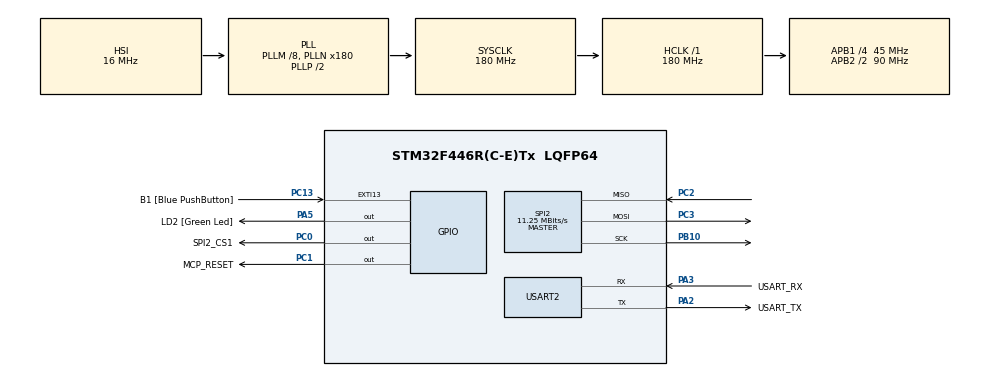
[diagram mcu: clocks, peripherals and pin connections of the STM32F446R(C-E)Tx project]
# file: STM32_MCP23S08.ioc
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Mcu.Family=STM32F4
Mcu.Name=STM32F446R(C-E)Tx
Mcu.Package=LQFP64
NVIC.PriorityGroup=NVIC_PRIORITYGROUP_0
PA13.GPIO_Label=TMS
PA13.Mode=Serial_Wire
PA13.Signal=SYS_JTMS-SWDIO
PA14.GPIO_Label=TCK
PA14.Mode=Serial_Wire
PA14.Signal=SYS_JTCK-SWCLK
PA2.GPIO_Label=USART_TX
PA2.Mode=Asynchronous
PA2.Signal=USART2_TX
PA3.GPIO_Label=USART_RX
PA3.Mode=Asynchronous
PA3.Signal=USART2_RX
PA5.GPIO_Label=LD2 [Green Led]
PA5.Signal=GPIO_Output
PB10.Mode=Full_Duplex_Master
PB10.Signal=SPI2_SCK
PB3.GPIO_Label=SWO
PB3.Signal=SYS_JTDO-SWO
PC0.GPIO_Label=SPI2_CS1
PC0.PinState=GPIO_PIN_SET
PC0.Signal=GPIO_Output
PC1.GPIO_Label=MCP_RESET
PC1.Signal=GPIO_Output
PC13.GPIO_Label=B1 [Blue PushButton]
PC13.GPIO_ModeDefaultEXTI=GPIO_MODE_IT_FALLING
PC13.Signal=GPXTI13
PC14-OSC32_IN.Mode=LSE-External-Oscillator
PC14-OSC32_IN.Signal=RCC_OSC32_IN
PC15-OSC32_OUT.Mode=LSE-External-Oscillator
PC15-OSC32_OUT.Signal=RCC_OSC32_OUT
PC2.Mode=Full_Duplex_Master
PC2.Signal=SPI2_MISO
PC3.Mode=Full_Duplex_Master
PC3.Signal=SPI2_MOSI
PH0-OSC_IN.Mode=HSE-External-Oscillator
PH0-OSC_IN.Signal=RCC_OSC_IN
PH1-OSC_OUT.Mode=HSE-External-Oscillator
PH1-OSC_OUT.Signal=RCC_OSC_OUT
ProjectManager.HeapSize=0x200
ProjectManager.StackSize=0x400
ProjectManager.TargetToolchain=Makefile
RCC.48MHZClocksFreq_Value=84000000
RCC.AHBFreq_Value=180000000
RCC.APB1CLKDivider=RCC_HCLK_DIV4
RCC.APB1Freq_Value=45000000
RCC.APB1TimFreq_Value=90000000
RCC.APB2CLKDivider=RCC_HCLK_DIV2
RCC.APB2Freq_Value=90000000
RCC.APB2TimFreq_Value=180000000
RCC.CortexFreq_Value=180000000
RCC.FLatency-AdvancedSettings=FLASH_LATENCY_5
RCC.HCLKFreq_Value=180000000
RCC.HSE_VALUE=8000000
RCC.HSI_VALUE=16000000
RCC.PLLM=8
RCC.PLLN=180
RCC.SYSCLKFreq_VALUE=180000000
RCC.SYSCLKSource=RCC_SYSCLKSOURCE_PLLCLK
RCC.USBFreq_Value=180000000
RCC.VCOOutputFreq_Value=360000000
SPI2.BaudRatePrescaler=SPI_BAUDRATEPRESCALER_4
SPI2.CalculateBaudRate=11.25 MBits/s
SPI2.Direction=SPI_DIRECTION_2LINES
SPI2.Mode=SPI_MODE_MASTER
SPI2.VirtualType=VM_MASTER
USART2.VirtualMode=VM_ASYNC
board=NUCLEO-F446RE

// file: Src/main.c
/* USER CODE BEGIN Header */
/**
  ******************************************************************************
  * @file           : main.c
  * @brief          : Main program body
  ******************************************************************************
  * @attention
  *
  * Copyright (c) 2023 STMicroelectronics.
  * All rights reserved.
  *
  * This software is licensed under terms that can be found in the LICENSE file
  * in the root directory of this software component.
  * If no LICENSE file comes with this software, it is provided AS-IS.
  *
  ******************************************************************************
  */
/* USER CODE END Header */
#include "main.h"
#include "spi.h"
#include "usart.h"
#include "gpio.h"

/* USER CODE BEGIN Includes */
#include "MCP23S08.h"
#include <stdio.h>
#include "string.h"
/* USER CODE END Includes */

void SystemClock_Config(void);

int main(void)
{

  /* MCU Configuration--------------------------------------------------------*/

  /* Reset of all peripherals, Initializes the Flash interface and the Systick. */
  HAL_Init();

  /* Configure the system clock */
  SystemClock_Config();

  /* Initialize all configured peripherals */
  MX_GPIO_Init();
  MX_SPI2_Init();
  MX_USART2_UART_Init();
  /* USER CODE BEGIN 2 */
  MCP23S08_init(0x40, &hspi2, MCP_RESET_GPIO_Port, MCP_RESET_Pin, 0x03);
  MCP23S08_set_pullup_resistor(0x40, 0x03);
  /* USER CODE END 2 */

  /* Infinite loop */
  /* USER CODE BEGIN WHILE */
  while (1) {
      /*
    uint8_t gpio[8] = {GP0, GP1, GP2, GP3, GP4, GP5, GP6, GP7};

    for (int i=0; i < (sizeof(gpio)/sizeof(gpio[0])); i++) {
        MCP23S08_GPIO_WritePin(0x40, gpio[i], GPIO_PIN_SET);
        HAL_Delay(500);
    }

    for (int i=0; i < 2; i++) {
        for (int j=0; j < (sizeof(gpio)/sizeof(gpio[0])); j++) {
            MCP23S08_GPIO_TogglePin(0x40, gpio[j]);
            HAL_Delay(100);
        }
    }

    for (int i=0; i < (sizeof(gpio)/sizeof(gpio[0])); i++) {
        MCP23S08_GPIO_WritePin(0x40, gpio[i], GPIO_PIN_RESET);
        HAL_Delay(500);
    }
*/
    if (MCP23S08_GPIO_ReadPin(0x40, GP0) == 0) HAL_GPIO_WritePin(LD2_GPIO_Port, LD2_Pin, GPIO_PIN_SET);
    else HAL_GPIO_WritePin(LD2_GPIO_Port, LD2_Pin, GPIO_PIN_RESET);
    if (MCP23S08_GPIO_ReadPin(0x40, GP1) == 0) MCP23S08_GPIO_WritePin(0x40, GP7, GPIO_PIN_SET);
    else MCP23S08_GPIO_WritePin(0x40, GP7, GPIO_PIN_RESET);
    if (MCP23S08_GPIO_ReadPin(0x40, GP0) == -1) {
        while (1) {
            HAL_GPIO_TogglePin(LD2_GPIO_Port, LD2_Pin);
            HAL_Delay(250);
        }
    }
    /* USER CODE END WHILE */

  }
}

void SystemClock_Config(void)
{
  RCC_OscInitTypeDef RCC_OscInitStruct = {0};
  RCC_ClkInitTypeDef RCC_ClkInitStruct = {0};

  /** Configure the main internal regulator output voltage
  */
  __HAL_RCC_PWR_CLK_ENABLE();
  __HAL_PWR_VOLTAGESCALING_CONFIG(PWR_REGULATOR_VOLTAGE_SCALE1);

  /** Initializes the RCC Oscillators according to the specified parameters
  * in the RCC_OscInitTypeDef structure.
  */
  RCC_OscInitStruct.OscillatorType = RCC_OSCILLATORTYPE_HSI;
  RCC_OscInitStruct.HSIState = RCC_HSI_ON;
  RCC_OscInitStruct.HSICalibrationValue = RCC_HSICALIBRATION_DEFAULT;
  RCC_OscInitStruct.PLL.PLLState = RCC_PLL_ON;
  RCC_OscInitStruct.PLL.PLLSource = RCC_PLLSOURCE_HSI;
  RCC_OscInitStruct.PLL.PLLM = 8;
  RCC_OscInitStruct.PLL.PLLN = 180;
  RCC_OscInitStruct.PLL.PLLP = RCC_PLLP_DIV2;
  RCC_OscInitStruct.PLL.PLLQ = 2;
  RCC_OscInitStruct.PLL.PLLR = 2;
  if (HAL_RCC_OscConfig(&RCC_OscInitStruct) != HAL_OK)
  {
    Error_Handler();
  }

  /** Activate the Over-Drive mode
  */
  if (HAL_PWREx_EnableOverDrive() != HAL_OK)
  {
    Error_Handler();
  }

  /** Initializes the CPU, AHB and APB buses clocks
  */
  RCC_ClkInitStruct.ClockType = RCC_CLOCKTYPE_HCLK|RCC_CLOCKTYPE_SYSCLK
                              |RCC_CLOCKTYPE_PCLK1|RCC_CLOCKTYPE_PCLK2;
  RCC_ClkInitStruct.SYSCLKSource = RCC_SYSCLKSOURCE_PLLCLK;
  RCC_ClkInitStruct.AHBCLKDivider = RCC_SYSCLK_DIV1;
  RCC_ClkInitStruct.APB1CLKDivider = RCC_HCLK_DIV4;
  RCC_ClkInitStruct.APB2CLKDivider = RCC_HCLK_DIV2;

  if (HAL_RCC_ClockConfig(&RCC_ClkInitStruct, FLASH_LATENCY_5) != HAL_OK)
  {
    Error_Handler();
  }
}

void Error_Handler(void)
{
  __disable_irq();
  while (1)
  {
  }
}
